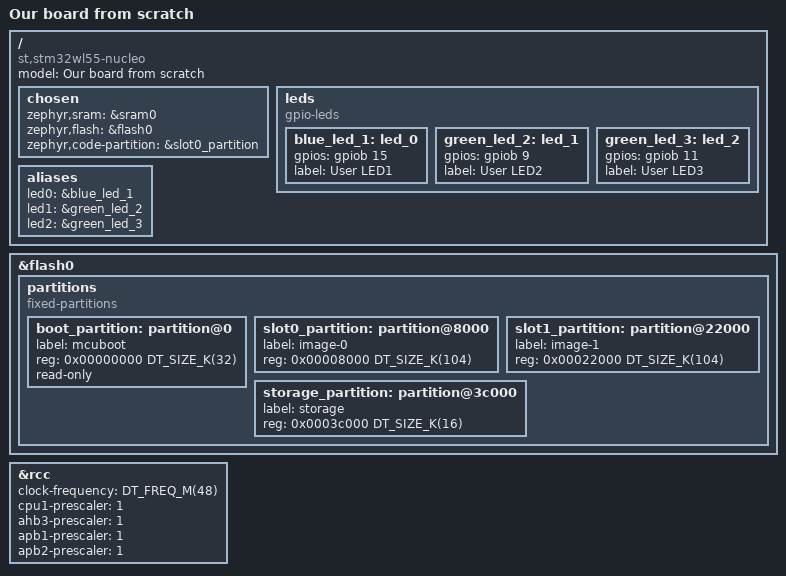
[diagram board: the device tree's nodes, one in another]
/dts-v1/;
#include <st/wl/stm32wl55Xc.dtsi>

/ {
	model = "Our board from scratch";
	compatible = "st,stm32wl55-nucleo";

	chosen {
		zephyr,sram = &sram0;
		zephyr,flash = &flash0;
		zephyr,code-partition = &slot0_partition;
	};

	leds: leds {
		compatible = "gpio-leds";

		blue_led_1: led_0 {
			gpios = <&gpiob 15 GPIO_ACTIVE_HIGH>;
			label = "User LED1";
		};

		green_led_2: led_1 {
			gpios = <&gpiob 9 GPIO_ACTIVE_HIGH>;
			label = "User LED2";
		};

		green_led_3: led_2 {
			gpios = <&gpiob 11 GPIO_ACTIVE_HIGH>;
			label = "User LED3";
		};
	};

	aliases {
		led0 = &blue_led_1;
		led1 = &green_led_2;
		led2 = &green_led_3;
	};
};


&flash0 {
	partitions {
		compatible = "fixed-partitions";
		#address-cells = <1>;
		#size-cells = <1>;

		boot_partition: partition@0 {
			label = "mcuboot";
			reg = <0x00000000 DT_SIZE_K(32)>;
			read-only;
		};

		slot0_partition: partition@8000 {
			label = "image-0";
			reg = <0x00008000 DT_SIZE_K(104)>;
		};

		slot1_partition: partition@22000 {
			label = "image-1";
			reg = <0x00022000 DT_SIZE_K(104)>;
		};

		/*
		 * Set 16kB of storage (8x2kB pages) at the end of the 256kB of
		 * flash.
		 */
		storage_partition: partition@3c000 {
			label = "storage";
			reg = <0x0003c000 DT_SIZE_K(16)>;
		};
	};
};

&rcc {
	clock-frequency = <DT_FREQ_M(48)>;
	cpu1-prescaler = <1>;
	ahb3-prescaler = <1>;
	apb1-prescaler = <1>;
	apb2-prescaler = <1>;
};
